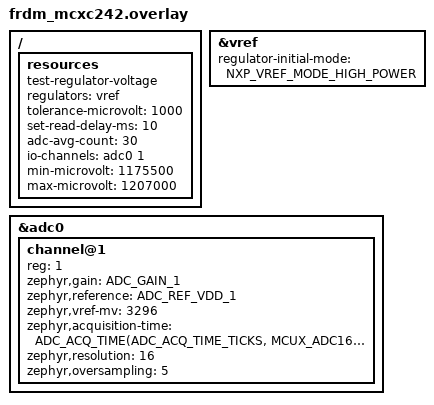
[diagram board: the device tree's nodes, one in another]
/*
 * Copyright 2025 NXP
 * SPDX-License-Identifier: Apache-2.0
 */

#include <zephyr/dt-bindings/regulator/nxp_vref.h>
#include <zephyr/dt-bindings/adc/mcux-adc16.h>

/* Connect J4-2 and J8-2 to test this case. */

/ {
	resources: resources {
		compatible = "test-regulator-voltage";
		regulators = <&vref>;
		tolerance-microvolt = <1000>;
		set-read-delay-ms = <10>;
		adc-avg-count = <30>;
		io-channels = <&adc0 1>;
		min-microvolt = <1175500>;
		max-microvolt = <1207000>;
	};
};

&vref {
	regulator-initial-mode = <NXP_VREF_MODE_HIGH_POWER>;
};

&adc0 {
	#address-cells = <1>;
	#size-cells = <0>;

	channel@1 {
		reg = <1>;
		zephyr,gain = "ADC_GAIN_1";
		zephyr,reference = "ADC_REF_VDD_1";
		zephyr,vref-mv = <3296>;
		zephyr,acquisition-time = <ADC_ACQ_TIME(ADC_ACQ_TIME_TICKS,
					MCUX_ADC16_ACQUISITION_TIME_24CYCLE)>;
		zephyr,resolution = <16>;
		zephyr,oversampling = <5>;
	};
};
